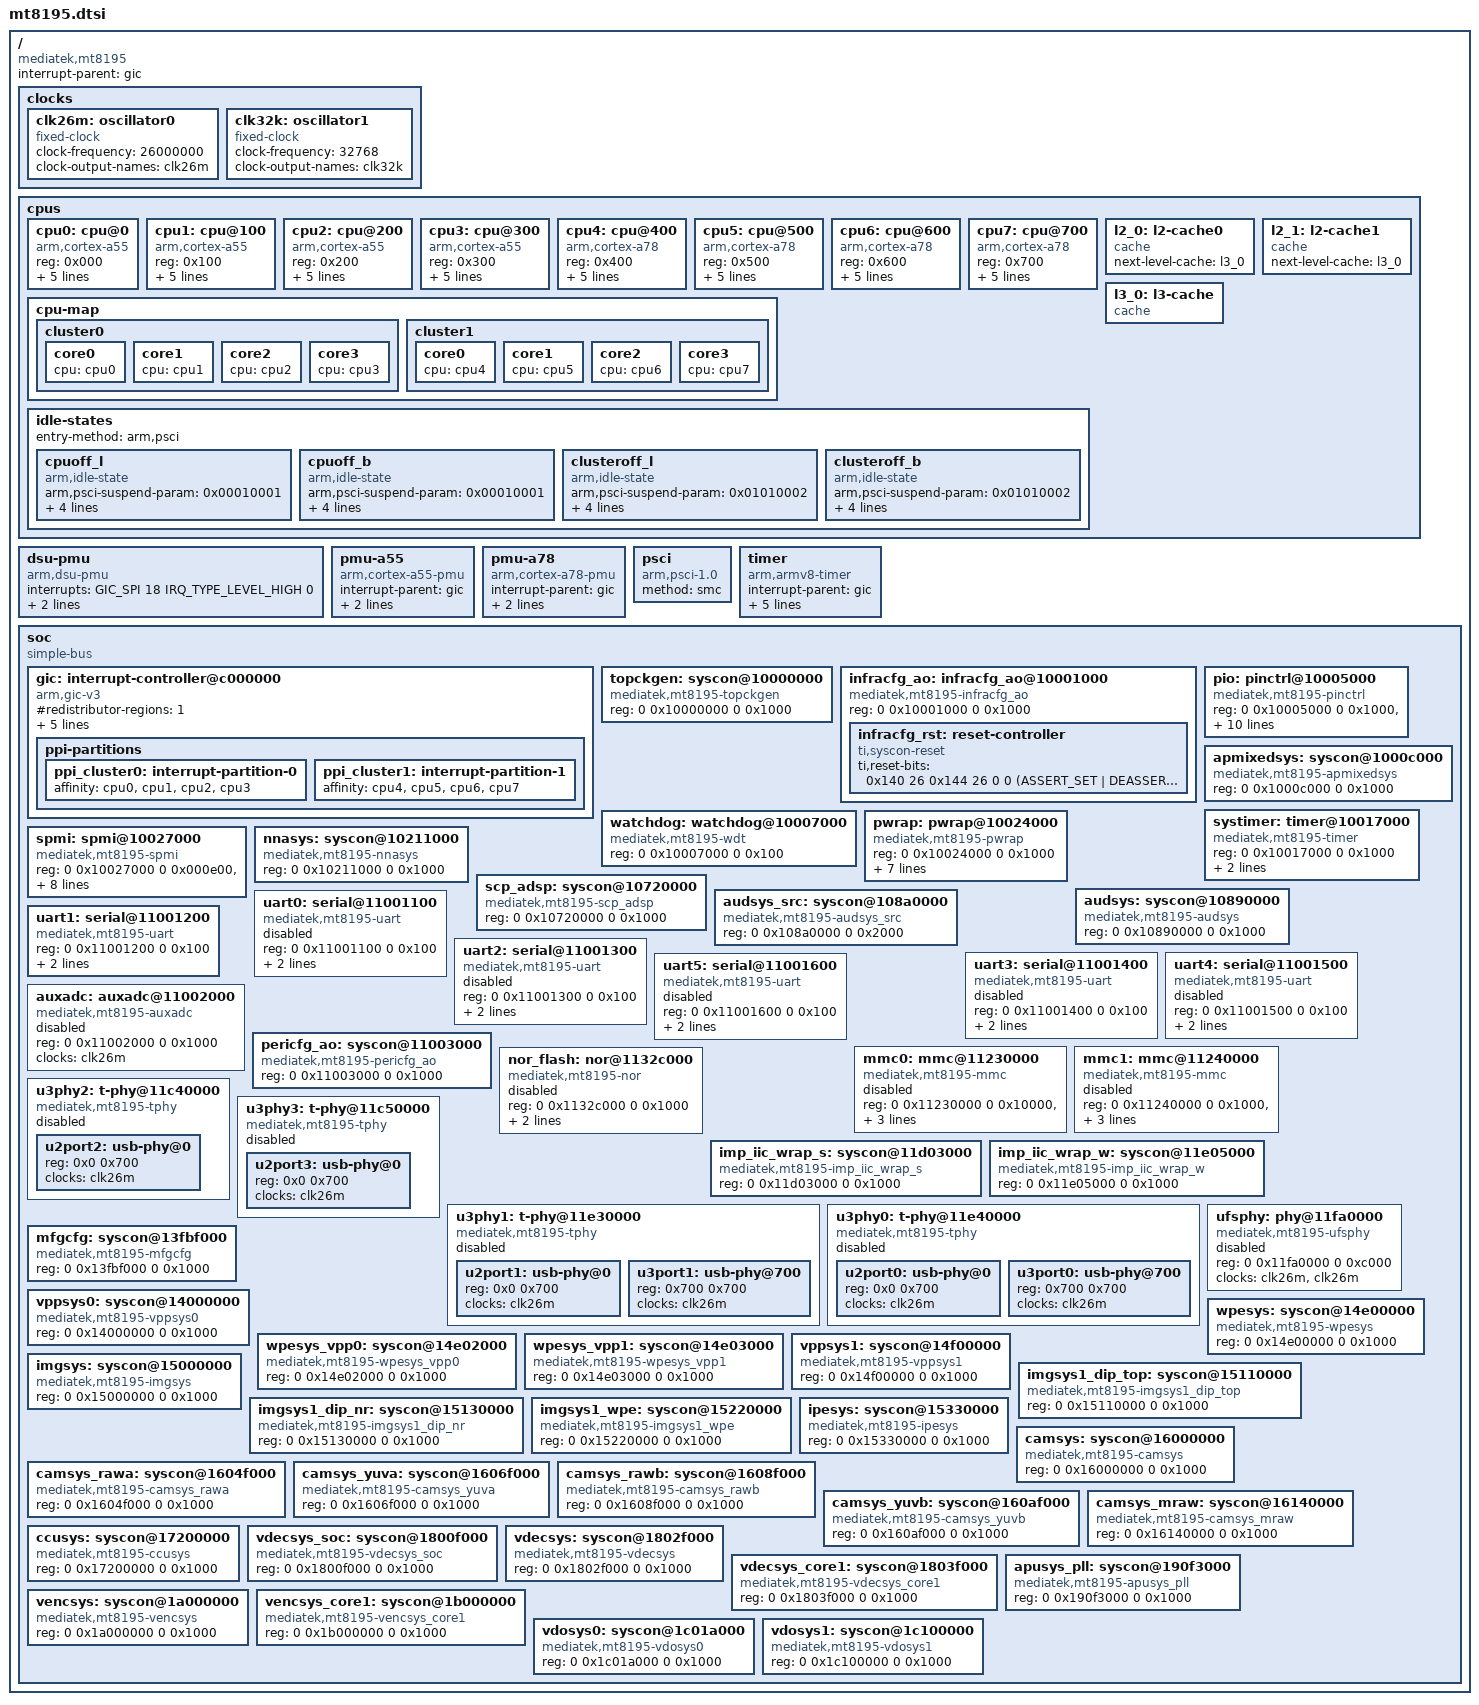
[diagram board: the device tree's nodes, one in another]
// SPDX-License-Identifier: (GPL-2.0 OR MIT)
/*
 * Copyright (c) 2021 MediaTek Inc.
 * Author: Seiya Wang <seiya.wang@mediatek.com>
 */

/dts-v1/;

#include <dt-bindings/clock/mt8195-clk.h>
#include <dt-bindings/interrupt-controller/arm-gic.h>
#include <dt-bindings/interrupt-controller/irq.h>
#include <dt-bindings/pinctrl/mt8195-pinfunc.h>
#include <dt-bindings/reset/ti-syscon.h>

/ {
	compatible = "mediatek,mt8195";
	interrupt-parent = <&gic>;
	#address-cells = <2>;
	#size-cells = <2>;

	clocks {
		clk26m: oscillator0 {
			compatible = "fixed-clock";
			#clock-cells = <0>;
			clock-frequency = <26000000>;
			clock-output-names = "clk26m";
		};

		clk32k: oscillator1 {
			compatible = "fixed-clock";
			#clock-cells = <0>;
			clock-frequency = <32768>;
			clock-output-names = "clk32k";
		};
	};

	cpus {
		#address-cells = <1>;
		#size-cells = <0>;

		cpu0: cpu@0 {
			device_type = "cpu";
			compatible = "arm,cortex-a55", "arm,armv8";
			reg = <0x000>;
			enable-method = "psci";
			clock-frequency = <1701000000>;
			capacity-dmips-mhz = <578>;
			cpu-idle-states = <&cpuoff_l &clusteroff_l>;
			next-level-cache = <&l2_0>;
			#cooling-cells = <2>;
		};

		cpu1: cpu@100 {
			device_type = "cpu";
			compatible = "arm,cortex-a55", "arm,armv8";
			reg = <0x100>;
			enable-method = "psci";
			clock-frequency = <1701000000>;
			capacity-dmips-mhz = <578>;
			cpu-idle-states = <&cpuoff_l &clusteroff_l>;
			next-level-cache = <&l2_0>;
			#cooling-cells = <2>;
		};

		cpu2: cpu@200 {
			device_type = "cpu";
			compatible = "arm,cortex-a55", "arm,armv8";
			reg = <0x200>;
			enable-method = "psci";
			clock-frequency = <1701000000>;
			capacity-dmips-mhz = <578>;
			cpu-idle-states = <&cpuoff_l &clusteroff_l>;
			next-level-cache = <&l2_0>;
			#cooling-cells = <2>;
		};

		cpu3: cpu@300 {
			device_type = "cpu";
			compatible = "arm,cortex-a55", "arm,armv8";
			reg = <0x300>;
			enable-method = "psci";
			clock-frequency = <1701000000>;
			capacity-dmips-mhz = <578>;
			cpu-idle-states = <&cpuoff_l &clusteroff_l>;
			next-level-cache = <&l2_0>;
			#cooling-cells = <2>;
		};

		cpu4: cpu@400 {
			device_type = "cpu";
			compatible = "arm,cortex-a78", "arm,armv8";
			reg = <0x400>;
			enable-method = "psci";
			clock-frequency = <2171000000>;
			capacity-dmips-mhz = <1024>;
			cpu-idle-states = <&cpuoff_b &clusteroff_b>;
			next-level-cache = <&l2_1>;
			#cooling-cells = <2>;
		};

		cpu5: cpu@500 {
			device_type = "cpu";
			compatible = "arm,cortex-a78", "arm,armv8";
			reg = <0x500>;
			enable-method = "psci";
			clock-frequency = <2171000000>;
			capacity-dmips-mhz = <1024>;
			cpu-idle-states = <&cpuoff_b &clusteroff_b>;
			next-level-cache = <&l2_1>;
			#cooling-cells = <2>;
		};

		cpu6: cpu@600 {
			device_type = "cpu";
			compatible = "arm,cortex-a78", "arm,armv8";
			reg = <0x600>;
			enable-method = "psci";
			clock-frequency = <2171000000>;
			capacity-dmips-mhz = <1024>;
			cpu-idle-states = <&cpuoff_b &clusteroff_b>;
			next-level-cache = <&l2_1>;
			#cooling-cells = <2>;
		};

		cpu7: cpu@700 {
			device_type = "cpu";
			compatible = "arm,cortex-a78", "arm,armv8";
			reg = <0x700>;
			enable-method = "psci";
			clock-frequency = <2171000000>;
			capacity-dmips-mhz = <1024>;
			cpu-idle-states = <&cpuoff_b &clusteroff_b>;
			next-level-cache = <&l2_1>;
			#cooling-cells = <2>;
		};

		cpu-map {
			cluster0 {
				core0 {
					cpu = <&cpu0>;
				};
				core1 {
					cpu = <&cpu1>;
				};
				core2 {
					cpu = <&cpu2>;
				};
				core3 {
					cpu = <&cpu3>;
				};
			};
			cluster1 {
				core0 {
					cpu = <&cpu4>;
				};
				core1 {
					cpu = <&cpu5>;
				};
				core2 {
					cpu = <&cpu6>;
				};
				core3 {
					cpu = <&cpu7>;
				};
			};
		};

		idle-states {
			entry-method = "arm,psci";
			cpuoff_l: cpuoff_l {
				compatible = "arm,idle-state";
				arm,psci-suspend-param = <0x00010001>;
				local-timer-stop;
				entry-latency-us = <50>;
				exit-latency-us = <95>;
				min-residency-us = <580>;
			};
			cpuoff_b: cpuoff_b {
				compatible = "arm,idle-state";
				arm,psci-suspend-param = <0x00010001>;
				local-timer-stop;
				entry-latency-us = <45>;
				exit-latency-us = <140>;
				min-residency-us = <740>;
			};
			clusteroff_l: clusteroff_l {
				compatible = "arm,idle-state";
				arm,psci-suspend-param = <0x01010002>;
				local-timer-stop;
				entry-latency-us = <55>;
				exit-latency-us = <155>;
				min-residency-us = <840>;
			};
			clusteroff_b: clusteroff_b {
				compatible = "arm,idle-state";
				arm,psci-suspend-param = <0x01010002>;
				local-timer-stop;
				entry-latency-us = <50>;
				exit-latency-us = <200>;
				min-residency-us = <1000>;
			};
		};

		l2_0: l2-cache0 {
			compatible = "cache";
			next-level-cache = <&l3_0>;
		};

		l2_1: l2-cache1 {
			compatible = "cache";
			next-level-cache = <&l3_0>;
		};

		l3_0: l3-cache {
			compatible = "cache";
		};
	};

	dsu-pmu {
		compatible = "arm,dsu-pmu";
		interrupts = <GIC_SPI 18 IRQ_TYPE_LEVEL_HIGH 0>;
		cpus = <&cpu0>, <&cpu1>, <&cpu2>, <&cpu3>,
		       <&cpu4>, <&cpu5>, <&cpu6>, <&cpu7>;
	};

	pmu-a55 {
		compatible = "arm,cortex-a55-pmu";
		interrupt-parent = <&gic>;
		interrupts = <GIC_PPI 7 IRQ_TYPE_LEVEL_HIGH &ppi_cluster0>;
	};

	pmu-a78 {
		compatible = "arm,cortex-a78-pmu";
		interrupt-parent = <&gic>;
		interrupts = <GIC_PPI 7 IRQ_TYPE_LEVEL_HIGH &ppi_cluster1>;
	};

	psci {
		compatible = "arm,psci-1.0";
		method = "smc";
	};

	timer: timer {
		compatible = "arm,armv8-timer";
		interrupt-parent = <&gic>;
		interrupts = <GIC_PPI 13 IRQ_TYPE_LEVEL_HIGH 0>,
			     <GIC_PPI 14 IRQ_TYPE_LEVEL_HIGH 0>,
			     <GIC_PPI 11 IRQ_TYPE_LEVEL_HIGH 0>,
			     <GIC_PPI 10 IRQ_TYPE_LEVEL_HIGH 0>;
		clock-frequency = <13000000>;
	};

	soc {
		#address-cells = <2>;
		#size-cells = <2>;
		compatible = "simple-bus";
		ranges;

		gic: interrupt-controller@c000000 {
			compatible = "arm,gic-v3";
			#interrupt-cells = <4>;
			#redistributor-regions = <1>;
			interrupt-parent = <&gic>;
			interrupt-controller;
			reg = <0 0x0c000000 0 0x40000>,
			      <0 0x0c040000 0 0x200000>;
			interrupts = <GIC_PPI 9 IRQ_TYPE_LEVEL_HIGH 0>;

			ppi-partitions {
				ppi_cluster0: interrupt-partition-0 {
					affinity = <&cpu0 &cpu1 &cpu2 &cpu3>;
				};
				ppi_cluster1: interrupt-partition-1 {
					affinity = <&cpu4 &cpu5 &cpu6 &cpu7>;
				};
			};
		};

		topckgen: syscon@10000000 {
			compatible = "mediatek,mt8195-topckgen", "syscon";
			reg = <0 0x10000000 0 0x1000>;
			#clock-cells = <1>;
		};

		infracfg_ao: infracfg_ao@10001000 {
			compatible = "mediatek,mt8195-infracfg_ao", "syscon", "simple-mfd";
			reg = <0 0x10001000 0 0x1000>;
			#clock-cells = <1>;

			infracfg_rst: reset-controller {
				compatible = "ti,syscon-reset";
				#reset-cells = <1>;
				ti,reset-bits = <
					0x140 26 0x144 26 0 0 (ASSERT_SET | DEASSERT_SET | STATUS_NONE)
				>;
			};
		};

		pio: pinctrl@10005000 {
			compatible = "mediatek,mt8195-pinctrl";
			reg = <0 0x10005000 0 0x1000>,
			      <0 0x11d30000 0 0x1000>,
			      <0 0x11d10000 0 0x1000>,
			      <0 0x11d40000 0 0x1000>,
			      <0 0x11e20000 0 0x1000>,
			      <0 0x11eb0000 0 0x1000>,
			      <0 0x11f40000 0 0x1000>,
			      <0 0x1000b000 0 0x1000>;
			reg-names = "iocfg0", "iocfg_bl", "iocfg_bm",
				    "iocfg_br", "iocfg_lm", "iocfg_rb",
				    "iocfg_tl", "eint";
			gpio-controller;
			#gpio-cells = <2>;
			gpio-ranges = <&pio 0 0 144>;
			interrupt-controller;
			interrupts = <GIC_SPI 212 IRQ_TYPE_LEVEL_HIGH 0>;
			#interrupt-cells = <2>;
		};

		watchdog: watchdog@10007000 {
			compatible = "mediatek,mt8195-wdt", "mediatek,mt6589-wdt";
			reg = <0 0x10007000 0 0x100>;
		};

		apmixedsys: syscon@1000c000 {
			compatible = "mediatek,mt8195-apmixedsys", "syscon";
			reg = <0 0x1000c000 0 0x1000>;
			#clock-cells = <1>;
		};

		systimer: timer@10017000 {
			compatible = "mediatek,mt8195-timer", "mediatek,mt6765-timer";
			reg = <0 0x10017000 0 0x1000>;
			interrupts = <GIC_SPI 265 IRQ_TYPE_LEVEL_HIGH 0>;
			clocks = <&clk26m>;
		};

		pwrap: pwrap@10024000 {
			compatible = "mediatek,mt8195-pwrap", "syscon";
			reg = <0 0x10024000 0 0x1000>;
			reg-names = "pwrap";
			interrupts = <GIC_SPI 243 IRQ_TYPE_LEVEL_HIGH 0>;
			clocks = <&infracfg_ao CLK_INFRA_AO_PMIC_AP>,
				 <&infracfg_ao CLK_INFRA_AO_PMIC_TMR>;
			clock-names = "spi", "wrap";
			assigned-clocks = <&topckgen CLK_TOP_PWRAP_ULPOSC_SEL>;
			assigned-clock-parents = <&topckgen CLK_TOP_ULPOSC_D10>;
		};

		spmi: spmi@10027000 {
			compatible = "mediatek,mt8195-spmi";
			reg = <0 0x10027000 0 0x000e00>,
			      <0 0x10029000 0 0x000100>;
			reg-names = "pmif", "spmimst";
			clocks = <&infracfg_ao CLK_INFRA_AO_PMIC_AP>,
				 <&infracfg_ao CLK_INFRA_AO_PMIC_TMR>,
				 <&topckgen CLK_TOP_SPMI_M_MST_SEL>;
			clock-names = "pmif_sys_ck",
				      "pmif_tmr_ck",
				      "spmimst_clk_mux";
			assigned-clocks = <&topckgen CLK_TOP_PWRAP_ULPOSC_SEL>;
			assigned-clock-parents = <&topckgen CLK_TOP_ULPOSC_D10>;
		};

		nnasys: syscon@10211000 {
			compatible = "mediatek,mt8195-nnasys", "syscon";
			reg = <0 0x10211000 0 0x1000>;
			#clock-cells = <1>;
		};

		scp_adsp: syscon@10720000 {
			compatible = "mediatek,mt8195-scp_adsp", "syscon";
			reg = <0 0x10720000 0 0x1000>;
			#clock-cells = <1>;
		};

		audsys: syscon@10890000 {
			compatible = "mediatek,mt8195-audsys", "syscon";
			reg = <0 0x10890000 0 0x1000>;
			#clock-cells = <1>;
		};

		audsys_src: syscon@108a0000 {
			compatible = "mediatek,mt8195-audsys_src", "syscon";
			reg = <0 0x108a0000 0 0x2000>;
			#clock-cells = <1>;
		};

		uart0: serial@11001100 {
			compatible = "mediatek,mt8195-uart", "mediatek,mt6577-uart";
			reg = <0 0x11001100 0 0x100>;
			interrupts = <GIC_SPI 141 IRQ_TYPE_LEVEL_HIGH 0>;
			clocks = <&clk26m>, <&clk26m>;
			clock-names = "baud", "bus";
			status = "disabled";
		};

		uart1: serial@11001200 {
			compatible = "mediatek,mt8195-uart", "mediatek,mt6577-uart";
			reg = <0 0x11001200 0 0x100>;
			interrupts = <GIC_SPI 142 IRQ_TYPE_LEVEL_HIGH 0>;
			clocks = <&clk26m>, <&clk26m>;
			clock-names = "baud", "bus";
		};

		uart2: serial@11001300 {
			compatible = "mediatek,mt8195-uart", "mediatek,mt6577-uart";
			reg = <0 0x11001300 0 0x100>;
			interrupts = <GIC_SPI 143 IRQ_TYPE_LEVEL_HIGH 0>;
			clocks = <&clk26m>, <&clk26m>;
			clock-names = "baud", "bus";
			status = "disabled";
		};

		uart3: serial@11001400 {
			compatible = "mediatek,mt8195-uart", "mediatek,mt6577-uart";
			reg = <0 0x11001400 0 0x100>;
			interrupts = <GIC_SPI 723 IRQ_TYPE_LEVEL_HIGH 0>;
			clocks = <&clk26m>, <&clk26m>;
			clock-names = "baud", "bus";
			status = "disabled";
		};

		uart4: serial@11001500 {
			compatible = "mediatek,mt8195-uart", "mediatek,mt6577-uart";
			reg = <0 0x11001500 0 0x100>;
			interrupts = <GIC_SPI 724 IRQ_TYPE_LEVEL_HIGH 0>;
			clocks = <&clk26m>, <&clk26m>;
			clock-names = "baud", "bus";
			status = "disabled";
		};

		uart5: serial@11001600 {
			compatible = "mediatek,mt8195-uart", "mediatek,mt6577-uart";
			reg = <0 0x11001600 0 0x100>;
			interrupts = <GIC_SPI 725 IRQ_TYPE_LEVEL_HIGH 0>;
			clocks = <&clk26m>, <&clk26m>;
			clock-names = "baud", "bus";
			status = "disabled";
		};

		auxadc: auxadc@11002000 {
			compatible = "mediatek,mt8195-auxadc", "mediatek,mt8173-auxadc";
			reg = <0 0x11002000 0 0x1000>;
			clocks = <&clk26m>;
			clock-names = "main";
			#io-channel-cells = <1>;
			status = "disabled";
		};

		pericfg_ao: syscon@11003000 {
			compatible = "mediatek,mt8195-pericfg_ao", "syscon";
			reg = <0 0x11003000 0 0x1000>;
			#clock-cells = <1>;
		};

		mmc0: mmc@11230000 {
			compatible = "mediatek,mt8195-mmc", "mediatek,mt8192-mmc";
			reg = <0 0x11230000 0 0x10000>,
			      <0 0x11f50000 0 0x1000>;
			interrupts = <GIC_SPI 131 IRQ_TYPE_LEVEL_HIGH 0>;
			clocks = <&clk26m>, <&clk26m>, <&clk26m>;
			clock-names = "source", "hclk", "source_cg";
			status = "disabled";
		};

		mmc1: mmc@11240000 {
			compatible = "mediatek,mt8195-mmc", "mediatek,mt8192-mmc";
			reg = <0 0x11240000 0 0x1000>,
			      <0 0x11c70000 0 0x1000>;
			interrupts = <GIC_SPI 135 IRQ_TYPE_LEVEL_HIGH 0>;
			clocks = <&clk26m>, <&clk26m>, <&clk26m>;
			clock-names = "source", "hclk", "source_cg";
			status = "disabled";
		};

		nor_flash: nor@1132c000 {
			compatible = "mediatek,mt8195-nor", "mediatek,mt8173-nor";
			reg = <0 0x1132c000 0 0x1000>;
			interrupts = <GIC_SPI 825 IRQ_TYPE_LEVEL_HIGH 0>;
			clocks = <&clk26m>, <&clk26m>;
			clock-names = "spi", "sf";
			#address-cells = <1>;
			#size-cells = <0>;
			status = "disabled";
		};

		u3phy2: t-phy@11c40000 {
			compatible = "mediatek,mt8195-tphy", "mediatek,generic-tphy-v2";
			#address-cells = <1>;
			#size-cells = <1>;
			ranges = <0 0 0x11c40000 0x700>;
			status = "disabled";

			u2port2: usb-phy@0 {
				reg = <0x0 0x700>;
				clocks = <&clk26m>;
				clock-names = "ref";
				#phy-cells = <1>;
			};
		};

		u3phy3: t-phy@11c50000 {
			compatible = "mediatek,mt8195-tphy", "mediatek,generic-tphy-v2";
			#address-cells = <1>;
			#size-cells = <1>;
			ranges = <0 0 0x11c50000 0x700>;
			status = "disabled";

			u2port3: usb-phy@0 {
				reg = <0x0 0x700>;
				clocks = <&clk26m>;
				clock-names = "ref";
				#phy-cells = <1>;
			};
		};

		imp_iic_wrap_s: syscon@11d03000 {
			compatible = "mediatek,mt8195-imp_iic_wrap_s", "syscon";
			reg = <0 0x11d03000 0 0x1000>;
			#clock-cells = <1>;
		};

		imp_iic_wrap_w: syscon@11e05000 {
			compatible = "mediatek,mt8195-imp_iic_wrap_w", "syscon";
			reg = <0 0x11e05000 0 0x1000>;
			#clock-cells = <1>;
		};

		u3phy1: t-phy@11e30000 {
			compatible = "mediatek,mt8195-tphy", "mediatek,generic-tphy-v2";
			#address-cells = <1>;
			#size-cells = <1>;
			ranges = <0 0 0x11e30000 0xe00>;
			status = "disabled";

			u2port1: usb-phy@0 {
				reg = <0x0 0x700>;
				clocks = <&clk26m>;
				clock-names = "ref";
				#phy-cells = <1>;
			};

			u3port1: usb-phy@700 {
				reg = <0x700 0x700>;
				clocks = <&clk26m>;
				clock-names = "ref";
				#phy-cells = <1>;
			};
		};

		u3phy0: t-phy@11e40000 {
			compatible = "mediatek,mt8195-tphy", "mediatek,generic-tphy-v2";
			#address-cells = <1>;
			#size-cells = <1>;
			ranges = <0 0 0x11e40000 0xe00>;
			status = "disabled";

			u2port0: usb-phy@0 {
				reg = <0x0 0x700>;
				clocks = <&clk26m>;
				clock-names = "ref";
				#phy-cells = <1>;
			};

			u3port0: usb-phy@700 {
				reg = <0x700 0x700>;
				clocks = <&clk26m>;
				clock-names = "ref";
				#phy-cells = <1>;
			};
		};

		ufsphy: phy@11fa0000 {
			compatible = "mediatek,mt8195-ufsphy", "mediatek,mt8183-ufsphy";
			reg = <0 0x11fa0000 0 0xc000>;
			clocks = <&clk26m>, <&clk26m>;
			clock-names = "unipro", "mp";
			#phy-cells = <0>;
			status = "disabled";
		};

		mfgcfg: syscon@13fbf000 {
			compatible = "mediatek,mt8195-mfgcfg", "syscon";
			reg = <0 0x13fbf000 0 0x1000>;
			#clock-cells = <1>;
		};

		vppsys0: syscon@14000000 {
			compatible = "mediatek,mt8195-vppsys0", "syscon";
			reg = <0 0x14000000 0 0x1000>;
			#clock-cells = <1>;
		};

		wpesys: syscon@14e00000 {
			compatible = "mediatek,mt8195-wpesys", "syscon";
			reg = <0 0x14e00000 0 0x1000>;
			#clock-cells = <1>;
		};

		wpesys_vpp0: syscon@14e02000 {
			compatible = "mediatek,mt8195-wpesys_vpp0", "syscon";
			reg = <0 0x14e02000 0 0x1000>;
			#clock-cells = <1>;
		};

		wpesys_vpp1: syscon@14e03000 {
			compatible = "mediatek,mt8195-wpesys_vpp1", "syscon";
			reg = <0 0x14e03000 0 0x1000>;
			#clock-cells = <1>;
		};

		vppsys1: syscon@14f00000 {
			compatible = "mediatek,mt8195-vppsys1", "syscon";
			reg = <0 0x14f00000 0 0x1000>;
			#clock-cells = <1>;
		};

		imgsys: syscon@15000000 {
			compatible = "mediatek,mt8195-imgsys", "syscon";
			reg = <0 0x15000000 0 0x1000>;
			#clock-cells = <1>;
		};

		imgsys1_dip_top: syscon@15110000 {
			compatible = "mediatek,mt8195-imgsys1_dip_top", "syscon";
			reg = <0 0x15110000 0 0x1000>;
			#clock-cells = <1>;
		};

		imgsys1_dip_nr: syscon@15130000 {
			compatible = "mediatek,mt8195-imgsys1_dip_nr", "syscon";
			reg = <0 0x15130000 0 0x1000>;
			#clock-cells = <1>;
		};

		imgsys1_wpe: syscon@15220000 {
			compatible = "mediatek,mt8195-imgsys1_wpe", "syscon";
			reg = <0 0x15220000 0 0x1000>;
			#clock-cells = <1>;
		};

		ipesys: syscon@15330000 {
			compatible = "mediatek,mt8195-ipesys", "syscon";
			reg = <0 0x15330000 0 0x1000>;
			#clock-cells = <1>;
		};

		camsys: syscon@16000000 {
			compatible = "mediatek,mt8195-camsys", "syscon";
			reg = <0 0x16000000 0 0x1000>;
			#clock-cells = <1>;
		};

		camsys_rawa: syscon@1604f000 {
			compatible = "mediatek,mt8195-camsys_rawa", "syscon";
			reg = <0 0x1604f000 0 0x1000>;
			#clock-cells = <1>;
		};

		camsys_yuva: syscon@1606f000 {
			compatible = "mediatek,mt8195-camsys_yuva", "syscon";
			reg = <0 0x1606f000 0 0x1000>;
			#clock-cells = <1>;
		};

		camsys_rawb: syscon@1608f000 {
			compatible = "mediatek,mt8195-camsys_rawb", "syscon";
			reg = <0 0x1608f000 0 0x1000>;
			#clock-cells = <1>;
		};

		camsys_yuvb: syscon@160af000 {
			compatible = "mediatek,mt8195-camsys_yuvb", "syscon";
			reg = <0 0x160af000 0 0x1000>;
			#clock-cells = <1>;
		};

		camsys_mraw: syscon@16140000 {
			compatible = "mediatek,mt8195-camsys_mraw", "syscon";
			reg = <0 0x16140000 0 0x1000>;
			#clock-cells = <1>;
		};

		ccusys: syscon@17200000 {
			compatible = "mediatek,mt8195-ccusys", "syscon";
			reg = <0 0x17200000 0 0x1000>;
			#clock-cells = <1>;
		};

		vdecsys_soc: syscon@1800f000 {
			compatible = "mediatek,mt8195-vdecsys_soc", "syscon";
			reg = <0 0x1800f000 0 0x1000>;
			#clock-cells = <1>;
		};

		vdecsys: syscon@1802f000 {
			compatible = "mediatek,mt8195-vdecsys", "syscon";
			reg = <0 0x1802f000 0 0x1000>;
			#clock-cells = <1>;
		};

		vdecsys_core1: syscon@1803f000 {
			compatible = "mediatek,mt8195-vdecsys_core1", "syscon";
			reg = <0 0x1803f000 0 0x1000>;
			#clock-cells = <1>;
		};

		apusys_pll: syscon@190f3000 {
			compatible = "mediatek,mt8195-apusys_pll", "syscon";
			reg = <0 0x190f3000 0 0x1000>;
			#clock-cells = <1>;
		};

		vencsys: syscon@1a000000 {
			compatible = "mediatek,mt8195-vencsys", "syscon";
			reg = <0 0x1a000000 0 0x1000>;
			#clock-cells = <1>;
		};

		vencsys_core1: syscon@1b000000 {
			compatible = "mediatek,mt8195-vencsys_core1", "syscon";
			reg = <0 0x1b000000 0 0x1000>;
			#clock-cells = <1>;
		};

		vdosys0: syscon@1c01a000 {
			compatible = "mediatek,mt8195-vdosys0", "syscon";
			reg = <0 0x1c01a000 0 0x1000>;
			#clock-cells = <1>;
		};

		vdosys1: syscon@1c100000 {
			compatible = "mediatek,mt8195-vdosys1", "syscon";
			reg = <0 0x1c100000 0 0x1000>;
			#clock-cells = <1>;
		};
	};
};
